# PY32F303 register map
Vendor: PUYA Co.Ltd; Series: ARMCM4; File version: 1.2
CPU: CM4 r0p1, little endian, MPU, FPU, 4 interrupt priority bits
Registers are 32-bit, read-write, reset 0x0 unless marked. A register's access mark holds for its fields unless they carry their own. Offsets are from the block's base; [hi:lo] are bit positions; {n}, {i} and the like mark numbered series.

## EXTI
Base 0x40010400
0x00 IMR
  [18:0] MR
0x04 EMR
  [18:0] MR
0x08 RTSR
  [18:0] TR
0x0C FTSR
  [18:0] TR
0x10 SWIER
  [18:0] SWIER
0x14 PR
  [18:0] PR

## FLASH
Base 0x40022000
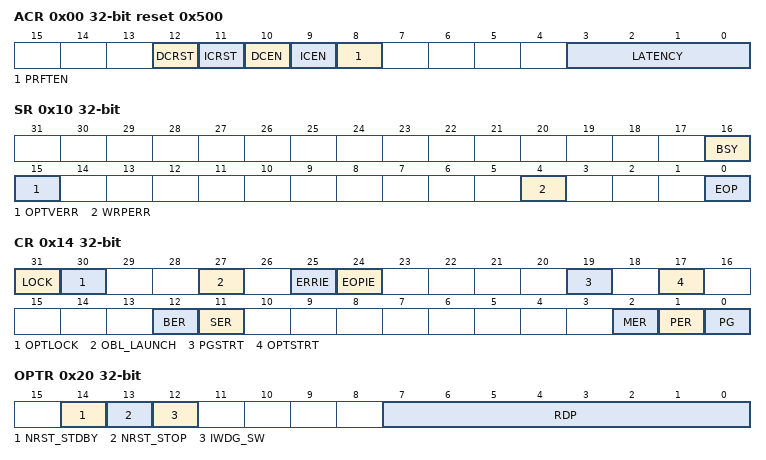
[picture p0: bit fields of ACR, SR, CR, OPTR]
0x00 ACR reset 0x500 (reset mask 0x70F)
  [12] DCRST, [11] ICRST, [10] DCEN, [9] ICEN, [8] PRFTEN, [3:0] LATENCY
0x08 KEYR wo
  [31:0] KEY
0x0C OPTKEYR wo
  [31:0] OPTKEY
0x10 SR
  [16] BSY ro, [15] OPTVERR, [4] WRPERR, [0] EOP
0x14 CR
  [31] LOCK, [30] OPTLOCK, [27] OBL_LAUNCH, [25] ERRIE, [24] EOPIE, [19] PGSTRT, [17] OPTSTRT, [12] BER, [11] SER, [2] MER, [1] PER, [0] PG
0x20 OPTR
  [14] NRST_STDBY, [13] NRST_STOP, [12] IWDG_SW, [7:0] RDP
0x2C WRPR
  [11:0] WRP

## GPIOA — desc GPIO
Base 0x48000000
Same registers: GPIOB 0x48000400, GPIOC 0x48000800, GPIOD 0x48000C00, GPIOE 0x48001000
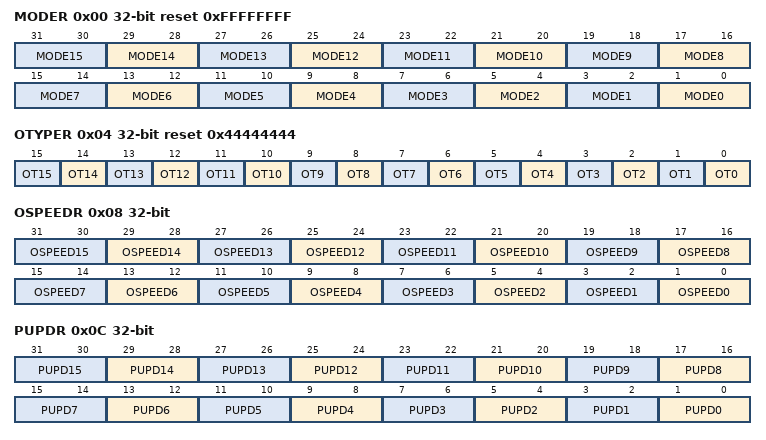
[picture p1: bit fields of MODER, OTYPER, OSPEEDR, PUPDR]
0x00 MODER reset 0xFFFFFFFF
  [2n+1:2n] MODE{n} (n=0..15)
0x04 OTYPER reset 0x44444444
  [n] OT{n} (n=0..15)
0x08 OSPEEDR
  [2n+1:2n] OSPEED{n} (n=0..15)
0x0C PUPDR
  [2n+1:2n] PUPD{n} (n=0..15)
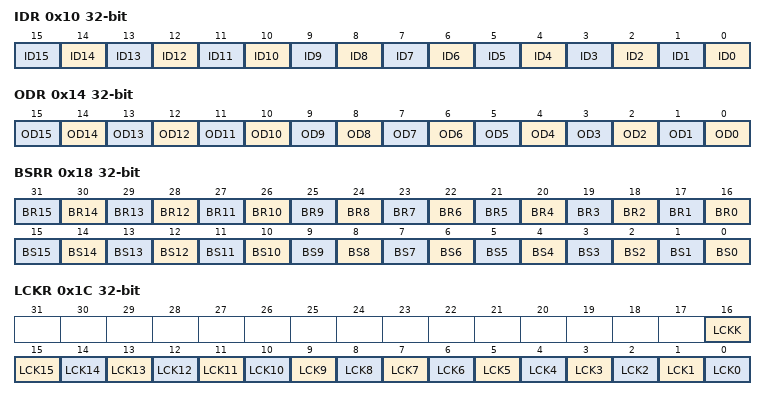
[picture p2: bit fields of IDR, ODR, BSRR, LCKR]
0x10 IDR ro
  [n] ID{n} (n=0..15)
0x14 ODR
  [n] OD{n} (n=0..15)
0x18 BSRR wo
  [n+16] BR{n} (n=0..15), [n] BS{n} (n=0..15)
0x1C LCKR
  [16] LCKK, [n] LCK{n} (n=0..15)
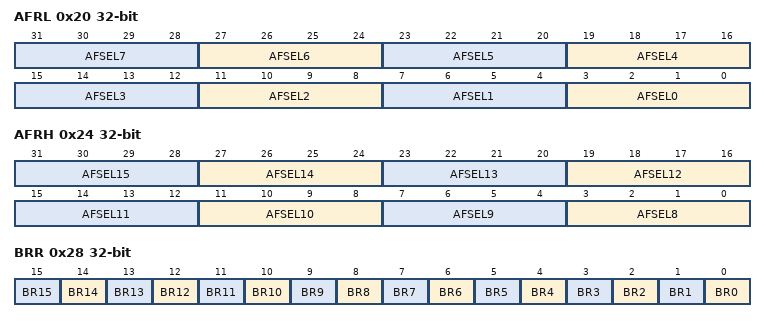
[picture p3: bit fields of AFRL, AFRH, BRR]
0x20 AFRL
  [4n+3:4n] AFSEL{n} (n=0..7)
0x24 AFRH
  [4n-29:4n-32] AFSEL{n} (n=8..15)
0x28 BRR wo
  [n] BR{n} (n=0..15)

## I2C1 — desc I2C
Base 0x40005400
Same registers: I2C2 0x40005800
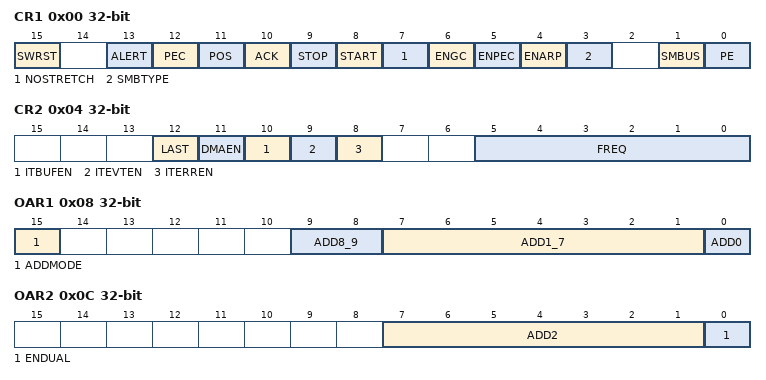
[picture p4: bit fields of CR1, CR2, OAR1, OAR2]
0x00 CR1
  [15] SWRST, [13] ALERT, [12] PEC, [11] POS, [10] ACK, [9] STOP, [8] START, [7] NOSTRETCH, [6] ENGC, [5] ENPEC, [4] ENARP, [3] SMBTYPE, [1] SMBUS, [0] PE
0x04 CR2
  [12] LAST, [11] DMAEN, [10] ITBUFEN, [9] ITEVTEN, [8] ITERREN, [5:0] FREQ
0x08 OAR1
  [15] ADDMODE
  [9:8] ADD8_9 — desc ADD
  [7:1] ADD1_7 — desc ADD
  [0] ADD0
0x0C OAR2
  [7:1] ADD2, [0] ENDUAL
0x10 DR
  [7:0] DR
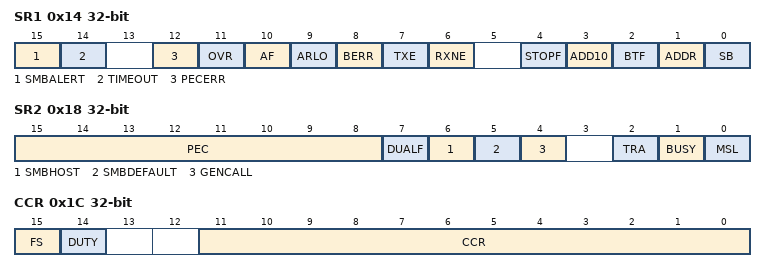
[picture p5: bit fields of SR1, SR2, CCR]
0x14 SR1
  [15] SMBALERT, [14] TIMEOUT, [12] PECERR, [11] OVR, [10] AF, [9] ARLO, [8] BERR, [7] TXE ro, [6] RXNE ro, [4] STOPF ro, [3] ADD10 ro, [2] BTF ro, [1] ADDR ro, [0] SB ro
0x18 SR2 ro
  [15:8] PEC, [7] DUALF, [6] SMBHOST, [5] SMBDEFAULT, [4] GENCALL, [2] TRA, [1] BUSY, [0] MSL
0x1C CCR
  [15] FS, [14] DUTY, [11:0] CCR
0x20 TRISE reset 0x2
  [5:0] TRISE

## IWDG
Base 0x40003000
0x00 KR wo
  [15:0] KEY
0x04 PR
  [2:0] PR
0x08 RLR
  [11:0] RL
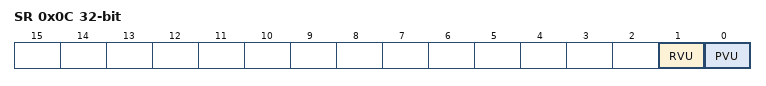
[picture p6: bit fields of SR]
0x0C SR ro
  [1] RVU, [0] PVU

## PWR
Base 0x40007000
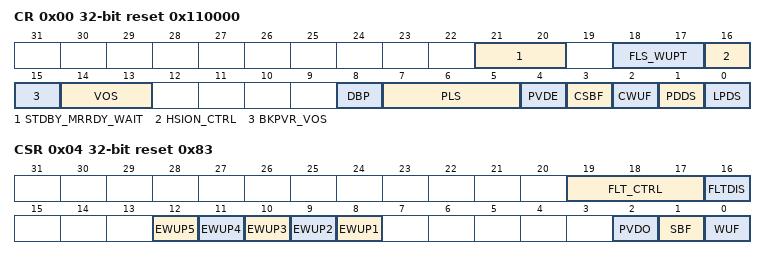
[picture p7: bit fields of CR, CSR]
0x00 CR reset 0x110000
  [21:20] STDBY_MRRDY_WAIT, [18:17] FLS_WUPT, [16] HSION_CTRL, [15] BKPVR_VOS, [14:13] VOS, [8] DBP, [7:5] PLS, [4] PVDE, [3] CSBF wo, [2] CWUF wo, [1] PDDS, [0] LPDS
0x04 CSR reset 0x83
  [19:17] FLT_CTRL, [16] FLTDIS, [n+7] EWUP{n} (n=1..5), [2] PVDO ro, [1] SBF ro, [0] WUF ro

## RCC
Base 0x40021000
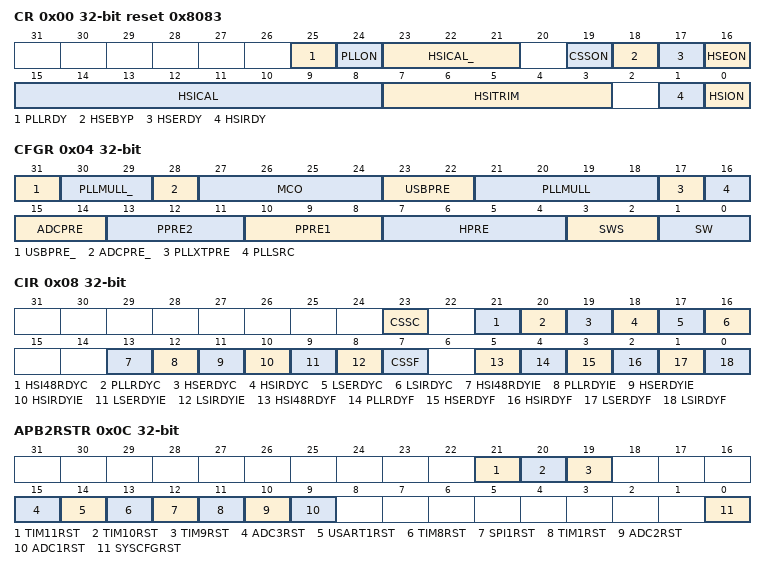
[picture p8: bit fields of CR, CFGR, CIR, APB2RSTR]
0x00 CR reset 0x8083 — clock control register
  [25] PLLRDY ro
  [24] PLLON — PLL enable
  [23:21] HSICAL_ ro — Internal high-speed clock calibration
  [19] CSSON
  [18] HSEBYP
  [17] HSERDY ro
  [16] HSEON
  [15:8] HSICAL ro — Internal high-speed clock calibration
  [7:3] HSITRIM — Internal high-speed clock trimming
  [1] HSIRDY ro
  [0] HSION
0x04 CFGR — clock configuration register
  [31] USBPRE_
  [30:29] PLLMULL_
  [28] ADCPRE_
  [27:24] MCO
  [23:22] USBPRE
  [21:18] PLLMULL
  [17] PLLXTPRE
  [16] PLLSRC
  [15:14] ADCPRE
  [13:11] PPRE2 — APB high-speed prescaler(APB2)
  [10:8] PPRE1 — APB Low speed prescaler (APB1)
  [7:4] HPRE
  [3:2] SWS
  [1:0] SW
0x08 CIR — clock interrupt register
  [23] CSSC wo, [21] HSI48RDYC wo, [20] PLLRDYC wo, [19] HSERDYC wo, [18] HSIRDYC wo, [17] LSERDYC wo, [16] LSIRDYC wo, [13] HSI48RDYIE, [12] PLLRDYIE, [11] HSERDYIE, [10] HSIRDYIE, [9] LSERDYIE, [8] LSIRDYIE, [7] CSSF, [5] HSI48RDYF ro, [4] PLLRDYF ro, [3] HSERDYF ro, [2] HSIRDYF ro, [1] LSERDYF ro, [0] LSIRDYF ro
0x0C APB2RSTR — APB2 peripheral reset register
  [21] TIM11RST, [20] TIM10RST, [19] TIM9RST, [15] ADC3RST, [14] USART1RST, [13] TIM8RST, [12] SPI1RST, [11] TIM1RST, [10] ADC2RST, [9] ADC1RST, [0] SYSCFGRST
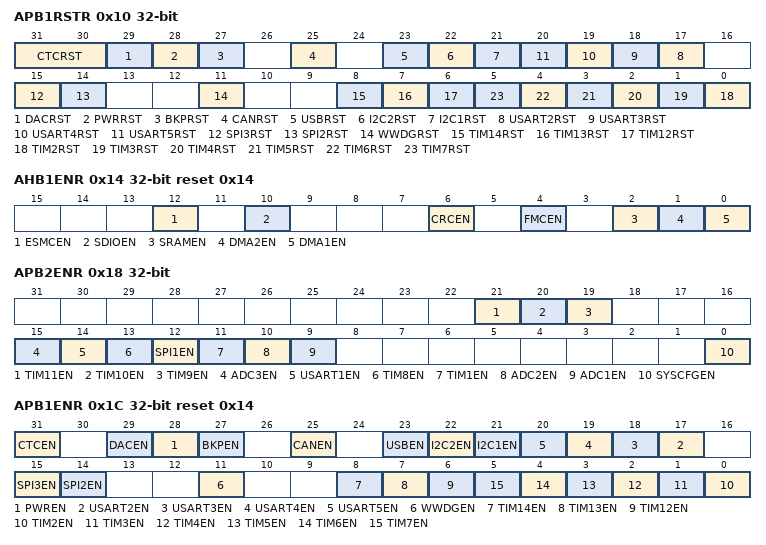
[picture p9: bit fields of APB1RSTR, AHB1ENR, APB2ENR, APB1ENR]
0x10 APB1RSTR — APB1 peripheral reset register
  [31:30] CTCRST, [29] DACRST, [28] PWRRST, [27] BKPRST, [25] CANRST, [23] USBRST, [22] I2C2RST, [21] I2C1RST, [n+15] USART{n}RST (n=2..5), [15] SPI3RST, [14] SPI2RST, [11] WWDGRST, [8] TIM14RST, [7] TIM13RST, [6] TIM12RST, [n-2] TIM{n}RST (n=2..7)
0x14 AHB1ENR reset 0x14 — AHB1 peripheral clock register
  [12] ESMCEN, [10] SDIOEN, [6] CRCEN, [4] FMCEN, [2] SRAMEN, [1] DMA2EN, [0] DMA1EN
0x18 APB2ENR — APB2 peripheral clock enable register
  [21] TIM11EN, [20] TIM10EN, [19] TIM9EN, [15] ADC3EN, [14] USART1EN, [13] TIM8EN, [12] SPI1EN, [11] TIM1EN, [10] ADC2EN, [9] ADC1EN, [0] SYSCFGEN
0x1C APB1ENR reset 0x14 — APB1 peripheral clock enable register
  [31] CTCEN, [29] DACEN, [28] PWREN, [27] BKPEN, [25] CANEN, [23] USBEN, [22] I2C2EN, [21] I2C1EN, [n+15] USART{n}EN (n=2..5), [15] SPI3EN, [14] SPI2EN, [11] WWDGEN, [8] TIM14EN, [7] TIM13EN, [6] TIM12EN, [n-2] TIM{n}EN (n=2..7)
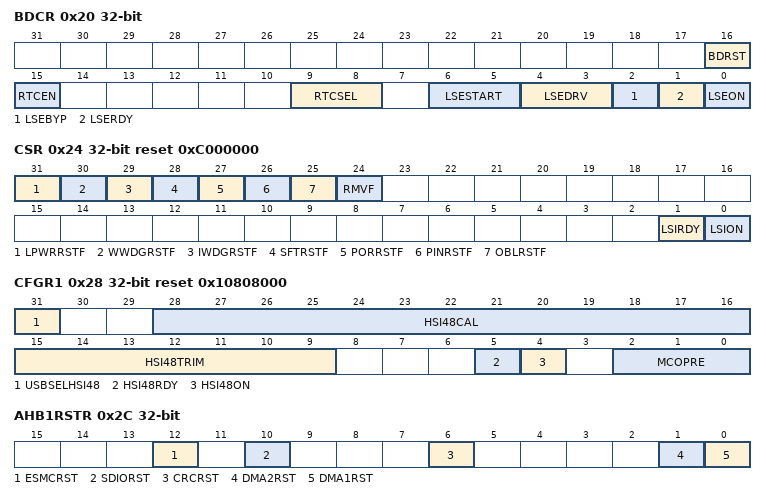
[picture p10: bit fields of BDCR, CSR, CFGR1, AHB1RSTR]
0x20 BDCR — Backup domain control register
  [16] BDRST, [15] RTCEN, [9:8] RTCSEL, [6:5] LSESTART, [4:3] LSEDRV, [2] LSEBYP, [1] LSERDY ro, [0] LSEON
0x24 CSR reset 0xC000000 — clock control & status register
  [31] LPWRRSTF ro, [30] WWDGRSTF ro, [29] IWDGRSTF ro, [28] SFTRSTF ro, [27] PORRSTF ro, [26] PINRSTF ro, [25] OBLRSTF ro, [24] RMVF, [1] LSIRDY ro, [0] LSION
0x28 CFGR1 reset 0x10808000 — clock configuration register 1
  [31] USBSELHSI48, [28:16] HSI48CAL ro, [15:9] HSI48TRIM, [5] HSI48RDY ro, [4] HSI48ON, [2:0] MCOPRE
0x2C AHB1RSTR — AHB1 peripheral reset register
  [12] ESMCRST, [10] SDIORST, [6] CRCRST, [1] DMA2RST, [0] DMA1RST
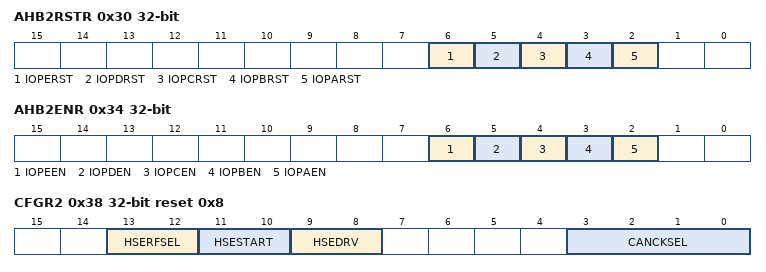
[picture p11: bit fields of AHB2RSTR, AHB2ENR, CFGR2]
0x30 AHB2RSTR — AHB2 peripheral reset register
  [6] IOPERST, [5] IOPDRST, [4] IOPCRST, [3] IOPBRST, [2] IOPARST
0x34 AHB2ENR — AHB2 peripheral clock register
  [6] IOPEEN, [5] IOPDEN, [4] IOPCEN, [3] IOPBEN, [2] IOPAEN
0x38 CFGR2 reset 0x8
  [13:12] HSERFSEL, [11:10] HSESTART, [9:8] HSEDRV, [3:0] CANCKSEL
